# MSS_MCRC register map
Vendor: Texas Instruments
Peripheral module from a debugger description file (folder xwr16xx).
Registers are 32-bit, access per field, no defined reset value unless marked. A register's access mark holds for its fields unless they carry their own. Offsets are as the file gives them; lines under a group give offsets from that group; [hi:lo] are bit positions; {n}, {i} and the like mark numbered series; 'fields as' and 'values as' point back to an identical list; <NAME> marks a mode.

## MSS_MCRC
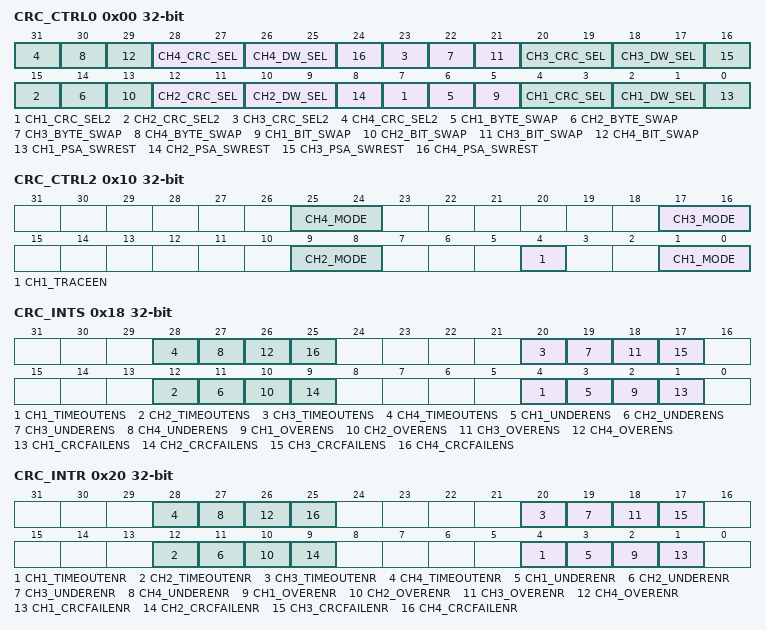
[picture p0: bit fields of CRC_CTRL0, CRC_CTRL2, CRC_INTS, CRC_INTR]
0x00 CRC_CTRL0 rw — Contains sw reset control bit to reset PSA
  [8n-1] CH{n}_CRC_SEL2 (n=1..4) — Refer "CH{n}_DW_SEL" field description
  [8n-2] CH{n}_BYTE_SWAP (n=1..4) — BYTE SWAP Enable across Data Size 0 – Byte Swap Disabled 1 – Byte Swap enabled.
  [8n-3] CH{n}_BIT_SWAP (n=1..4) — msb/lsb SWAPPING 0 – msb (most significant bit First) 1 – lsb (least significant bit First)
  [28:27] CH4_CRC_SEL — CRC type select. {CH1_CRC_SEL2,CH1_CRC_SEL[1:0]} 000 – CRC-64 001 - CRC-16 010 – CRC-32 100 - VDA CAN, SAE-J1850 CRC-8 101 - H2F, Autosar 4.0 110 - CASTAGNOLI, iSCSI 111 / 011 - E2E Profile 4
  [8n-6:8n-7] CH{n}_DW_SEL (n=1..4) — CRC Data Size select. 000 – 64 bit Data Size 001 - 16 bit Data Size 010 – 32 Bit Data Size
  [8n-8] CH{n}_PSA_SWREST (n=1..4) — Channel {n} PSA Software Reset. When set, the PSA Signature Register is reset to all zero. Software reset does not reset software reset bit itself. Therefore, CPU is required to clear this bit by writing a ‘0’. 0 = PSA Signature Register not reset 1 = PSA Signature Register reset
  [20:19] CH3_CRC_SEL — CRC type select. {CH1_CRC_SEL2,CH1_CRC_SEL[1:0]} 000 – CRC-64 001 - CRC-16 010 – CRC-32 100 - VDA CAN, SAE-J1850 CRC-8 101 - H2F, Autosar 4.0 110 - CASTAGNOLI, iSCSI 111 / 011 - E2E Profile 4
  [12:11] CH2_CRC_SEL — CRC type select. {CH1_CRC_SEL2,CH1_CRC_SEL[1:0]} 000 – CRC-64 001 - CRC-16 010 – CRC-32 100 - VDA CAN, SAE-J1850 CRC-8 101 - H2F, Autosar 4.0 110 - CASTAGNOLI, iSCSI 111 / 011 - E2E Profile 4
  [4:3] CH1_CRC_SEL — CRC type select. {CH1_CRC_SEL2,CH1_CRC_SEL[1:0]} 000 – CRC-64 001 - CRC-16 010 – CRC-32 100 - VDA CAN, SAE-J1850 CRC-8 101 - H2F, Autosar 4.0 110 - CASTAGNOLI, iSCSI 111 / 011 - E2E Profile 4
0x08 CRC_CTRL1 — Contains power down control bit
  [0] PWDN rw — Power Down. When set, MCRC moduleMCRC Module is put in power down mode. 0 = MCRC is not in power down mode 1 = MCRC is in power down mode
0x10 CRC_CTRL2 — Contains channel mode, data trace enable control bits
  [8n-7:8n-8] CH{n}_MODE rw (n=1..4) — Channel {n} Mode: 0 0 = Data Capture mode. In this mode, the PSA Signature Register does not compress data when it is written. Any data written to PSA Signature Register is simply captured by PSA Signature Register without any compression. This mode can be used to plant seed value into the PSA register 0 1 = AUTO mode 1 0 = reserved 1 1 = Full-CPU mode
  [4] CH1_TRACEEN rw — Channel 1 Data Trace Enable. When set, the channel is put into data trace mode. The channel snoops on the CPU VBUSM, ITCM, DTCM buses for any read transaction. Any read data on these buses is compressed by the PSA Signature Register. When suspend is on, the PSA Signature Register does not compress any read data on these buses. 0 = Data Trace disable 1 = Data Trace enable
0x18 CRC_INTS — Write one to a bit to enable a interrupt
  [8n-4] CH{n}_TIMEOUTENS rw (n=1..4) — Channel {n} Timeout Interrupt Enable Bit. Writing a one to this bit enable the timeout interrupt. Writing a zero has no effect. Reading from this bit gives the status (interrupt enable/disable). User and privileged mode read: 0 = Timeout Interrupt disable 1 = Timeout Interrupt enable User and privileged mode write: 0 = Has no effect 1 = Timeout Interrupt enable
  [8n-5] CH{n}_UNDERENS rw (n=1..4) — Channel {n} Underrun Interrupt Enable Bit. Writing a one to this bit enable the underrun interrupt. Writing a zero has no effect. Reading from this bit gives the status (interrupt enable/disable). User and privileged mode read: 0 = Underrun Interrupt disable 1 = Underrun Interrupt enable User and privileged mode write: 0 = Has no effect 1 = Underrun Interrupt enable
  [8n-6] CH{n}_OVERENS rw (n=1..4) — Channel {n} Overrun Interrupt Enable Bit. Writing a one to this bit enable the overrun interrupt. Writing a zero has no effect. Reading from this bit gives the status (interrupt enable/disable). User and privileged mode read: 0 = Overrun Interrupt disable 1 = Overrun Interrupt enable User and privileged mode write: 0 = Has no effect 1 = Overrun Interrupt enable
  [8n-7] CH{n}_CRCFAILENS rw (n=1..4) — Channel {n} CRC Fail Interrupt Enable Bit. Writing a one to this bit enable the CRC fail interrupt. Writing a zero has no effect. Reading from this bit gives the status (interrupt enable/disable). User and privileged mode read: 0 = CRC Fail Interrupt disable 1 = CRC Fail Interrupt enable User and privileged mode write: 0 = Has no effect 1 = CRC Fail Interrupt enable
0x20 CRC_INTR — Write one to a bit to disable a interrupt
  [8n-4] CH{n}_TIMEOUTENR rw (n=1..4) — Channel {n} Timeout Interrupt Disable Bit. Writing a one to this bit disable the timeout interrupt. Writing a zero has no effect. Reading from this bit gives the status (interrupt enable/disable). User and privileged mode read: 0 = Timeout Interrupt disable 1 = Timeout Interrupt enable User and privileged mode write: 0 = Has no effect 1 = Timeout Interrupt disable
  [8n-5] CH{n}_UNDERENR rw (n=1..4) — Channel {n} Underrun Interrupt Disable Bit. Writing a one to this bit disable the underrun interrupt. Writing a zero has no effect. Reading from this bit gives the status (interrupt enable/dis- able). User and privileged mode read: 0 = Underrun Interrupt disable 1 = Underrun Interrupt enable User and privileged mode write: 0 = Has no effect 1 = Underrun Interrupt disable
  [8n-6] CH{n}_OVERENR rw (n=1..4) — Channel {n} Overrun Interrupt Disable Bit. Writing a one to this bit disable the overrun interrupt. Writing a zero has no effect. Reading from this bit gives the status (interrupt enable/disable). User and privileged mode read: 0 = Overrun Interrupt disable 1 = Overrun Interrupt enable User and privileged mode write: 0 = Has no effect 1 = Overrun Interrupt disable
  [8n-7] CH{n}_CRCFAILENR rw (n=1..4) — Channel {n} CRC Fail Interrupt Disable Bit. Writing a one to this bit disable the CRC fail interrupt. Writing a zero has no effect. Reading from this bit gives the status (interrupt enable/disable). User and privileged mode read: 0 = CRC Fail Interrupt disable 1 = CRC Fail Interrupt enable User and privileged mode write: 0 = Has no effect 1 = CRC Fail Interrupt disable
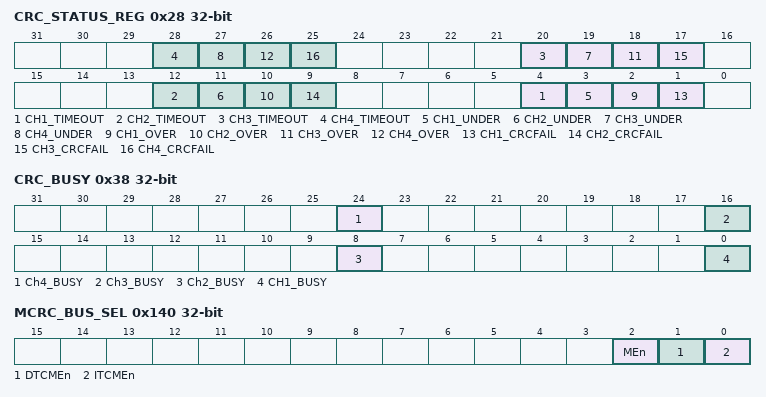
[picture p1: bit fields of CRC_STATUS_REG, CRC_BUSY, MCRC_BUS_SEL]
0x28 CRC_STATUS_REG — Contains interrupt flags for different types of interrupt
  [8n-4] CH{n}_TIMEOUT rw (n=1..4) — Channel {n} CRC Timeout Status Flag. This bit is cleared by writing a ’1’ to it only. Writing ’0’ has no effect. This bit is set in AUTO mode. 0 = No timeout interrupt is active 1 = Timeout interrupt is active
  [8n-5] CH{n}_UNDER rw (n=1..4) — Channel {n} CRC Underrun Status Flag. This bit is cleared by writing a ’1’ to it only. Writing ’0’ has no effect. This bit is set in AUTO mode only 0 = No underrun interrupt is active 1 = Underrun interrupt is active
  [8n-6] CH{n}_OVER rw (n=1..4) — Channel {n} CRC Overrun Status Flag. This bit is cleared by writing a ’1’ to it only. Writing ’0’ has no effect. This bit is set in AUTO mode 0 = No overrun interrupt is active 1 = Overrun interrupt is active
  [8n-7] CH{n}_CRCFAIL rw (n=1..4) — Channel {n} CRC Compare Fail Status Flag. This bit is cleared by writing a ’1’ to it only. Writing ’0’ has no effect. This bit is set in AUTO mode only. 0 = No CRC compare fail interrupt is active 1 = CRC compare fail interrupt is active
0x30 CRC_INT_OFFSET_REG — Contains the interrupt offset vector address
  [7:0] OFSTREG rw — CRC Interrupt Offset. This register indicates the highest priority pending interrupt vector address. Reading the offset register auto- matically clear the respective interrupt flag. Please reference Table 1–3. for details.
0x38 CRC_BUSY ro — Contains the busy flag for each channel
  [24] Ch4_BUSY — Ch4_BUSY. During AUTO mode, the busy flag is set when the first data pattern of the block is compressed and remains set until the the last data pattern of the block is compressed. The flag is cleared when the last data pattern of the block is compressed.
  [16] Ch3_BUSY — Ch3_BUSY. During AUTO mode, the busy flag is set when the first data pattern of the block is compressed and remains set until the the last data pattern of the block is compressed. The flag is cleared when the last data pattern of the block is compressed.
  [8] Ch2_BUSY — Ch2_BUSY. During AUTO mode, the busy flag is set when the first data pattern of the block is compressed and remains set until the the last data pattern of the block is compressed. The flag is cleared when the last data pattern of the block is compressed.
  [0] CH1_BUSY — CH1_BUSY. During AUTO mode, the busy flag is set when the first data pattern of the block is compressed and remains set until the the last data pattern of the block is compressed. The flag is cleared when the last data pattern of the block is compressed.
{0x0+0x40*i} CRC_PCOUNT_REG{i} (i=1..4) — Channel {i} preload register for the pattern count
  [19:0] CRC_PAT_COUNT{i} rw — Channel {i} Pattern Counter Preload Register. This register con- tains the number of data patterns in one sector to be compressed before a CRC is performed.
{0x4+0x40*i} CRC_SCOUNT_REG{i} (i=1..4) — Channel {i} preload register for the sector count
  [15:0] CRC_SEC_COUNT{i} rw — Channel {i} Sector Counter Preload Register. This register con- tains the number of sectors in one block of memory.
0x48 CRC_CURSEC_REG1 — Channel 1 current sector register contains the sector number which causes CRC failure
  [15:0] CRC_CURSEC1 rw — Channel 1 Current Sector ID Register. In AUTO mode, this register contains the current sector number of which the signature verification fails. The sector counter is a free running up counter. When a sector fails, the erroneous sector number is logged into current sector ID register and the CRC fail interrupt is generated The sector ID register is frozen until it is read and the CRC fail status bit is cleared by CPU. While it is frozen, it does not capture another erroneous sector number. When this condition happens, an overrun interrupt is generated instead. Once the register is read and the CRC fail interrupt flag is cleared it can capture new erro- neous sector number.
{0xC+0x40*i} CRC_WDTOPLD{i} (i=1..4) — Channel {i} timeout pre-load value to check if within a given time DMA initiates a block transfer
  [23:0] CRC_WDTOPLD{i} rw — Channel {i} Watchdog Timeout Counter Preload Register. This register contains the number of clock cycles within which the DMA must transfer the next block of data patterns.
{0x10+0x40*i} CRC_BCTOPLD{i} (i=1..4) — Channel {i} timeout pre-load value to check if one block of patterns are compressed with a given time
  [23:0] CRC_BCTOPLD{i} rw — Channel {i} Block Complete Timeout Counter Preload Regis- ter. This register contains the number of clock cycles within which the CRC for an entire block needs to complete before a timeout interrupt is generated.
{0x20+0x40*i} PSA_SIGREGL{i} rw (i=1..4) — Channel {i} PSA signature low register
  [31:0] PSASIG{i}_31_0 — Channel {i} PSA Signature Low Register. This register contains the value stored at PSASIG{i}[31:0] register.
{0x24+0x40*i} PSA_SIGREGH{i} rw (i=1..4) — Channel {i} PSA signature high register
  [31:0] PSA_SIG{i}_63_32 — Channel {i} PSA Signature High Register. This register contains the value stored at PSASIG{i}[63:32] register.
{0x28+0x40*i} CRC_REGL{i} rw (i=1..4) — Channel {i} CRC value low register
  [31:0] CRC{i}_31_0 — Channel {i} CRC Value Low Register. This register contains the current known good signature value stored at CRC{i}[31:0] regis- ter.
{0x2C+0x40*i} CRC_REGH{i} rw (i=1..4) — Channel {i} CRC value high register
  [31:0] CRC{i}_63_32 — Channel {i} CRC Value High Register. This register contains the current known good signature value stored at CRC{i}[63:32] regis- ter.
{0x30+0x40*i} PSA_SECSIGREGL{i} ro (i=1..4) — Channel {i} PSA sector signature low regis-ter
  [31:0] PSASECSIG{i}_31_0 — Channel {i} PSA Sector Signature Low Register. This register contains the value stored at PSASECSIG{i}[31:0] register.
{0x34+0x40*i} PSA_SECSIGREGH{i} ro (i=1..4) — Channel {i} PSA sector signature high regis-ter
  [31:0] PSASECSIG{i}_63_32 — Channel {i} PSA Sector Signature High Register. This register contains the value stored at PSASECSIG{i}[63:32] register.
{0x38+0x40*i} RAW_DATAREGL{i} ro (i=1..4) — Channel {i} un-compressed raw data low register
  [31:0] RAW_DATA{i}_31_0 — Channel {i} Raw Data Low Register. This register contains bit 31:0 of the un-compressed raw data.
0x7C RAW_DATAREGH1 ro — Channel 1 un-compressed raw data high register
  [31:0] RAW_DATA1_63_32 — Channel 1 Raw Data High Register. This register contains bit 63:32 of the un-compressed raw data.
{0x8+0x40*i} CRC_CURSEC_REG{i} (i=2..4) — Channel {i} current sector register contains the sector number which causes CRC fail-ure
  [15:0] CRC_CURSEC{i} rw — Channel {i} Current Sector ID Register. In AUTO mode, this register contains the current sector number of which the signature verification fails. The sector counter is a free running up counter. When a sector fails, the erroneous sector number is logged into current sector ID register and the CRC fail interrupt is generated The sector ID register is frozen until it is read and the CRC fail status bit is cleared by CPU. While it is frozen, it does not capture another erroneous sector number. When this condition happens, an overrun interrupt is generated instead. Once the register is read and the CRC fail interrupt flag is cleared it can capture new erro- neous sector number.
{0x3C+0x40*i} RAW_DATAREGH{i} ro (i=2..4) — Channel {i} un-compressed raw data high Register
  [31:0] RAW_DATA{i}_63_32 — Channel {i} Raw Data High Register. This register contains bit 63:32 of the un-compressed raw data.
0x140 MCRC_BUS_SEL — Disables either or all tracing of data buses
  [2] MEn rw — MEn. Enable/disables the tracing of VBUSM 0: Tracing of VBUSM master bus has been disabled 1: Tracing of VBUSM master bus has been enabled
  [1] DTCMEn rw — DTCMEn. Enable/disables the tracing of data TCM 0: Tracing of DTCM_ODD and DTCM_EVEN buses have been disabled 1: Tracing of DTCM_ODD and DTCM_EVEN buses have been enabled
  [0] ITCMEn rw — ITCMEn. Enable/disables the tracing of instruction TCM 0: Tracing of ITCM bus has been disabled 1: Tracing of ITCM bus has been enabled
